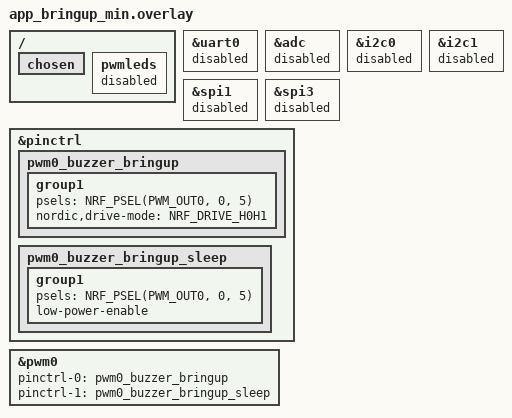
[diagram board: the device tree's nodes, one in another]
/*
 * Minimal bring-up: P0.04 GPIO high; P0.05 = pwm0 channel 0 @ ~4 kHz (see main_blinky.c).
 * Overrides DK pwm0 pin from on-board LED to P0.05 (BUZZER_EN).
 *
 * printk uses Segger RTT, not UART — uart0 stays disabled so nothing muxes P0.05 as RTS.
 *
 * west build ... -DDTC_OVERLAY_FILE=app_bringup_min.overlay
 */

#include <zephyr/dt-bindings/pinctrl/nrf-pinctrl.h>

/ {
    chosen {
        /delete-property/ zephyr,console;
        /delete-property/ zephyr,shell-uart;
        /delete-property/ zephyr,uart-mcumgr;
        /delete-property/ zephyr,bt-mon-uart;
        /delete-property/ zephyr,bt-c2h-uart;
    };

    /*
     * DK stock devicetree has pwm-leds on pwm0 ch0 for the green LED. Our overlay
     * moves PWM_OUT0 to P0.05 for bring-up; that driver still claimed ch0 and
     * could leave the peripheral busy or overwrite timing. Disable for this image.
     */
    pwmleds {
        status = "disabled";
    };
};

&uart0 {
	status = "disabled";
};

&adc {
	status = "disabled";
};

&i2c0 {
	status = "disabled";
};

&i2c1 {
	status = "disabled";
};

&spi1 {
	status = "disabled";
};

&spi3 {
	status = "disabled";
};

&pinctrl {
	pwm0_buzzer_bringup: pwm0_buzzer_bringup {
		group1 {
			psels = <NRF_PSEL(PWM_OUT0, 0, 5)>;
			nordic,drive-mode = <NRF_DRIVE_H0H1>;
		};
	};

	pwm0_buzzer_bringup_sleep: pwm0_buzzer_bringup_sleep {
		group1 {
			psels = <NRF_PSEL(PWM_OUT0, 0, 5)>;
			low-power-enable;
		};
	};
};

&pwm0 {
	status = "okay";
	pinctrl-0 = <&pwm0_buzzer_bringup>;
	pinctrl-1 = <&pwm0_buzzer_bringup_sleep>;
	pinctrl-names = "default", "sleep";
};
